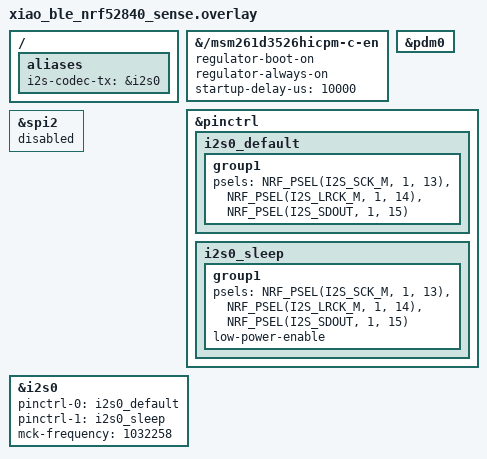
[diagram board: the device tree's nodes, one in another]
/*
 * Copyright The Zephyr Project Contributors
 *
 * SPDX-License-Identifier: Apache-2.0
 */

/*
 * Onboard PDM microphone to an I2S amplifier with no control interface, such
 * as a MAX98357A, wired to D8 (BCLK), D9 (LRCLK) and D10 (DIN).
 */

/ {
	aliases {
		i2s-codec-tx = &i2s0;
	};
};

&{/msm261d3526hicpm-c-en} {
	regulator-boot-on;
	regulator-always-on;
	startup-delay-us = <10000>;
};

dmic_dev: &pdm0 {
	status = "okay";
};

&pinctrl {
	i2s0_default: i2s0_default {
		group1 {
			psels = <NRF_PSEL(I2S_SCK_M, 1, 13)>,
				<NRF_PSEL(I2S_LRCK_M, 1, 14)>,
				<NRF_PSEL(I2S_SDOUT, 1, 15)>;
		};
	};

	i2s0_sleep: i2s0_sleep {
		group1 {
			psels = <NRF_PSEL(I2S_SCK_M, 1, 13)>,
				<NRF_PSEL(I2S_LRCK_M, 1, 14)>,
				<NRF_PSEL(I2S_SDOUT, 1, 15)>;
			low-power-enable;
		};
	};
};

/* D8-D10 are also the spi2 pins. */
&spi2 {
	status = "disabled";
};

/* 32 MHz / 31: with ratio 64 this matches the PDM clock at 16129 Hz. */
&i2s0 {
	status = "okay";
	pinctrl-0 = <&i2s0_default>;
	pinctrl-1 = <&i2s0_sleep>;
	pinctrl-names = "default", "sleep";
	mck-frequency = <1032258>;
};
